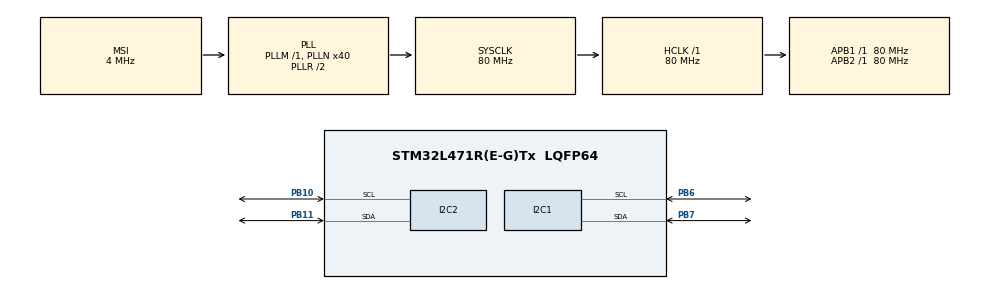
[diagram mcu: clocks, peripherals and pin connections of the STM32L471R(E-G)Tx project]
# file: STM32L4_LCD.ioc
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I2C1.Timing=0x10909CEC
I2C2.Timing=0x10909CEC
Mcu.Family=STM32L4
Mcu.Name=STM32L471R(E-G)Tx
Mcu.Package=LQFP64
NVIC.PriorityGroup=NVIC_PRIORITYGROUP_4
PB10.Mode=I2C
PB10.Signal=I2C2_SCL
PB11.Mode=I2C
PB11.Signal=I2C2_SDA
PB6.Mode=I2C
PB6.Signal=I2C1_SCL
PB7.Mode=I2C
PB7.Signal=I2C1_SDA
ProjectManager.HeapSize=0x200
ProjectManager.StackSize=0x400
ProjectManager.TargetToolchain=MDK-ARM V5.32
RCC.AHBFreq_Value=80000000
RCC.APB1Freq_Value=80000000
RCC.APB1TimFreq_Value=80000000
RCC.APB2Freq_Value=80000000
RCC.APB2TimFreq_Value=80000000
RCC.CortexFreq_Value=80000000
RCC.HCLKFreq_Value=80000000
RCC.HSE_VALUE=8000000
RCC.HSI_VALUE=16000000
RCC.LSE_VALUE=32768
RCC.MSI_VALUE=4000000
RCC.PLLN=40
RCC.SYSCLKFreq_VALUE=80000000
RCC.SYSCLKSource=RCC_SYSCLKSOURCE_PLLCLK
RCC.VCOOutputFreq_Value=160000000
board=custom

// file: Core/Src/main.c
/* USER CODE BEGIN Header */
/**
  ******************************************************************************
  * @file           : main.c
  * @brief          : Main program body
  ******************************************************************************
  * @attention
  *
  * Copyright (c) 2022 STMicroelectronics.
  * All rights reserved.
  *
  * This software is licensed under terms that can be found in the LICENSE file
  * in the root directory of this software component.
  * If no LICENSE file comes with this software, it is provided AS-IS.
  *
  ******************************************************************************
  */
/* USER CODE END Header */
#include "main.h"

/* USER CODE BEGIN Includes */
#include "stdio.h"
#include "stdint.h"
#include "stdlib.h"

/* USER CODE END Includes */

/* USER CODE BEGIN PTD */
#include "sys_lcd_public.h"
/* USER CODE END PTD */

I2C_HandleTypeDef hi2c1;
I2C_HandleTypeDef hi2c2;

void SystemClock_Config(void);
static void MX_GPIO_Init(void);
static void MX_I2C1_Init(void);
static void MX_I2C2_Init(void);

int main(void)
{

  /* MCU Configuration--------------------------------------------------------*/

  /* Reset of all peripherals, Initializes the Flash interface and the Systick. */
  HAL_Init();

  /* Configure the system clock */
  SystemClock_Config();

  /* Initialize all configured peripherals */
  MX_GPIO_Init();
  MX_I2C1_Init();
  MX_I2C2_Init();
  /* USER CODE BEGIN 2 */
	sys_lcd_init();
  /* USER CODE END 2 */

  /* Infinite loop */
  while (1)
  {

    /* USER CODE BEGIN 3 */

		sys_lcd_send_string("Eda CELIK");
		HAL_Delay(1000);
		sys_lcd_clear();
		sys_lcd_put_cur(1,0);
		sys_lcd_send_string("from BAYLAN");

  }
  /* USER CODE END 3 */
}

void SystemClock_Config(void)
{
  RCC_OscInitTypeDef RCC_OscInitStruct = {0};
  RCC_ClkInitTypeDef RCC_ClkInitStruct = {0};

  /** Configure the main internal regulator output voltage
  */
  if (HAL_PWREx_ControlVoltageScaling(PWR_REGULATOR_VOLTAGE_SCALE1) != HAL_OK)
  {
    Error_Handler();
  }

  /** Initializes the RCC Oscillators according to the specified parameters
  * in the RCC_OscInitTypeDef structure.
  */
  RCC_OscInitStruct.OscillatorType = RCC_OSCILLATORTYPE_MSI;
  RCC_OscInitStruct.MSIState = RCC_MSI_ON;
  RCC_OscInitStruct.MSICalibrationValue = 0;
  RCC_OscInitStruct.MSIClockRange = RCC_MSIRANGE_6;
  RCC_OscInitStruct.PLL.PLLState = RCC_PLL_ON;
  RCC_OscInitStruct.PLL.PLLSource = RCC_PLLSOURCE_MSI;
  RCC_OscInitStruct.PLL.PLLM = 1;
  RCC_OscInitStruct.PLL.PLLN = 40;
  RCC_OscInitStruct.PLL.PLLP = RCC_PLLP_DIV7;
  RCC_OscInitStruct.PLL.PLLQ = RCC_PLLQ_DIV2;
  RCC_OscInitStruct.PLL.PLLR = RCC_PLLR_DIV2;
  if (HAL_RCC_OscConfig(&RCC_OscInitStruct) != HAL_OK)
  {
    Error_Handler();
  }

  /** Initializes the CPU, AHB and APB buses clocks
  */
  RCC_ClkInitStruct.ClockType = RCC_CLOCKTYPE_HCLK|RCC_CLOCKTYPE_SYSCLK
                              |RCC_CLOCKTYPE_PCLK1|RCC_CLOCKTYPE_PCLK2;
  RCC_ClkInitStruct.SYSCLKSource = RCC_SYSCLKSOURCE_PLLCLK;
  RCC_ClkInitStruct.AHBCLKDivider = RCC_SYSCLK_DIV1;
  RCC_ClkInitStruct.APB1CLKDivider = RCC_HCLK_DIV1;
  RCC_ClkInitStruct.APB2CLKDivider = RCC_HCLK_DIV1;

  if (HAL_RCC_ClockConfig(&RCC_ClkInitStruct, FLASH_LATENCY_4) != HAL_OK)
  {
    Error_Handler();
  }
}

static void MX_I2C1_Init(void)
{

  hi2c1.Instance = I2C1;
  hi2c1.Init.Timing = 0x10909CEC;
  hi2c1.Init.OwnAddress1 = 0;
  hi2c1.Init.AddressingMode = I2C_ADDRESSINGMODE_7BIT;
  hi2c1.Init.DualAddressMode = I2C_DUALADDRESS_DISABLE;
  hi2c1.Init.OwnAddress2 = 0;
  hi2c1.Init.OwnAddress2Masks = I2C_OA2_NOMASK;
  hi2c1.Init.GeneralCallMode = I2C_GENERALCALL_DISABLE;
  hi2c1.Init.NoStretchMode = I2C_NOSTRETCH_DISABLE;
  if (HAL_I2C_Init(&hi2c1) != HAL_OK)
  {
    Error_Handler();
  }

  /** Configure Analogue filter
  */
  if (HAL_I2CEx_ConfigAnalogFilter(&hi2c1, I2C_ANALOGFILTER_ENABLE) != HAL_OK)
  {
    Error_Handler();
  }

  /** Configure Digital filter
  */
  if (HAL_I2CEx_ConfigDigitalFilter(&hi2c1, 0) != HAL_OK)
  {
    Error_Handler();
  }

}

static void MX_I2C2_Init(void)
{

  hi2c2.Instance = I2C2;
  hi2c2.Init.Timing = 0x10909CEC;
  hi2c2.Init.OwnAddress1 = 0;
  hi2c2.Init.AddressingMode = I2C_ADDRESSINGMODE_7BIT;
  hi2c2.Init.DualAddressMode = I2C_DUALADDRESS_DISABLE;
  hi2c2.Init.OwnAddress2 = 0;
  hi2c2.Init.OwnAddress2Masks = I2C_OA2_NOMASK;
  hi2c2.Init.GeneralCallMode = I2C_GENERALCALL_DISABLE;
  hi2c2.Init.NoStretchMode = I2C_NOSTRETCH_DISABLE;
  if (HAL_I2C_Init(&hi2c2) != HAL_OK)
  {
    Error_Handler();
  }

  /** Configure Analogue filter
  */
  if (HAL_I2CEx_ConfigAnalogFilter(&hi2c2, I2C_ANALOGFILTER_ENABLE) != HAL_OK)
  {
    Error_Handler();
  }

  /** Configure Digital filter
  */
  if (HAL_I2CEx_ConfigDigitalFilter(&hi2c2, 0) != HAL_OK)
  {
    Error_Handler();
  }

}

static void MX_GPIO_Init(void)
{

  /* GPIO Ports Clock Enable */
  __HAL_RCC_GPIOB_CLK_ENABLE();

}

void Error_Handler(void)
{
  __disable_irq();
  while (1)
  {
  }
}
